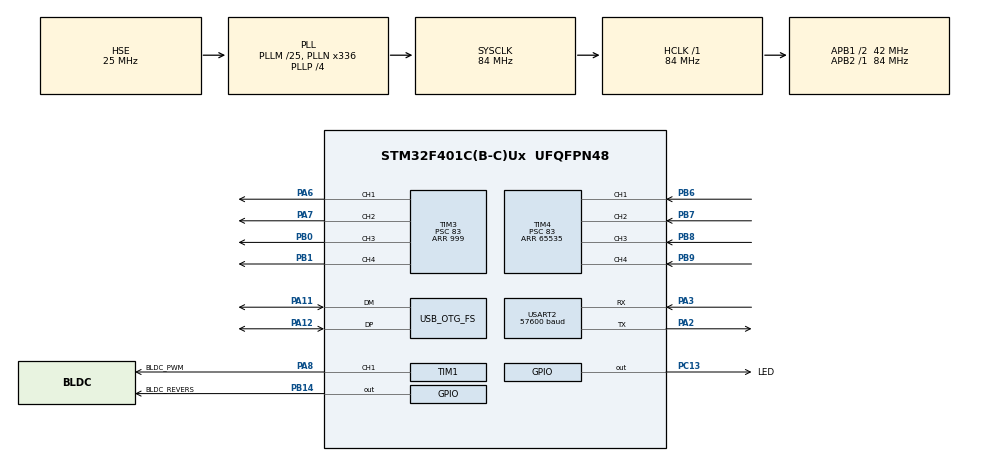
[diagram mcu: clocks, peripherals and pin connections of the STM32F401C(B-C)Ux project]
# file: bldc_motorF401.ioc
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Dma.Request0=USART2_RX
Dma.Request1=USART2_TX
Dma.USART2_RX.0.Direction=DMA_PERIPH_TO_MEMORY
Dma.USART2_RX.0.FIFOMode=DMA_FIFOMODE_DISABLE
Dma.USART2_RX.0.Instance=DMA1_Stream5
Dma.USART2_RX.0.MemDataAlignment=DMA_MDATAALIGN_BYTE
Dma.USART2_RX.0.MemInc=DMA_MINC_ENABLE
Dma.USART2_RX.0.Mode=DMA_NORMAL
Dma.USART2_RX.0.PeriphDataAlignment=DMA_PDATAALIGN_BYTE
Dma.USART2_RX.0.PeriphInc=DMA_PINC_DISABLE
Dma.USART2_RX.0.Priority=DMA_PRIORITY_LOW
Dma.USART2_TX.1.Direction=DMA_MEMORY_TO_PERIPH
Dma.USART2_TX.1.FIFOMode=DMA_FIFOMODE_DISABLE
Dma.USART2_TX.1.Instance=DMA1_Stream6
Dma.USART2_TX.1.MemDataAlignment=DMA_MDATAALIGN_BYTE
Dma.USART2_TX.1.MemInc=DMA_MINC_ENABLE
Dma.USART2_TX.1.Mode=DMA_NORMAL
Dma.USART2_TX.1.PeriphDataAlignment=DMA_PDATAALIGN_BYTE
Dma.USART2_TX.1.PeriphInc=DMA_PINC_DISABLE
Dma.USART2_TX.1.Priority=DMA_PRIORITY_LOW
Mcu.Family=STM32F4
Mcu.Name=STM32F401C(B-C)Ux
Mcu.Package=UFQFPN48
NVIC.DMA1_Stream5_IRQn=true\:0\:0\:false\:false\:true\:false\:true
NVIC.DMA1_Stream6_IRQn=true\:0\:0\:false\:false\:true\:false\:true
NVIC.OTG_FS_IRQn=true\:0\:0\:false\:false\:true\:false\:true
NVIC.PriorityGroup=NVIC_PRIORITYGROUP_4
NVIC.TIM4_IRQn=true\:0\:0\:false\:false\:true\:true\:true
NVIC.USART2_IRQn=true\:0\:0\:false\:false\:true\:true\:true
PA11.Mode=Device_Only
PA11.Signal=USB_OTG_FS_DM
PA12.Mode=Device_Only
PA12.Signal=USB_OTG_FS_DP
PA13.Mode=Serial_Wire
PA13.Signal=SYS_JTMS-SWDIO
PA14.Mode=Serial_Wire
PA14.Signal=SYS_JTCK-SWCLK
PA2.Mode=Asynchronous
PA2.Signal=USART2_TX
PA3.Mode=Asynchronous
PA3.Signal=USART2_RX
PA6.Signal=S_TIM3_CH1
PA7.Signal=S_TIM3_CH2
PA8.GPIO_Label=BLDC_PWM
PA8.GPIO_ModeDefaultPP=GPIO_MODE_AF_OD
PA8.GPIO_Speed=GPIO_SPEED_FREQ_VERY_HIGH
PA8.Signal=S_TIM1_CH1
PB0.Signal=S_TIM3_CH3
PB1.Signal=S_TIM3_CH4
PB14.GPIO_Label=BLDC_REVERS
PB14.GPIO_ModeDefaultOutputPP=GPIO_MODE_OUTPUT_OD
PB14.GPIO_PuPd=GPIO_NOPULL
PB14.Signal=GPIO_Output
PB6.Signal=S_TIM4_CH1
PB7.Signal=S_TIM4_CH2
PB8.Signal=S_TIM4_CH3
PB9.Signal=S_TIM4_CH4
PC13-ANTI_TAMP.GPIO_Label=LED
PC13-ANTI_TAMP.Signal=GPIO_Output
PC14-OSC32_IN.Mode=LSE-External-Oscillator
PC14-OSC32_IN.Signal=RCC_OSC32_IN
PC15-OSC32_OUT.Mode=LSE-External-Oscillator
PC15-OSC32_OUT.Signal=RCC_OSC32_OUT
PH0\ -\ OSC_IN.Mode=HSE-External-Oscillator
PH0\ -\ OSC_IN.Signal=RCC_OSC_IN
PH1\ -\ OSC_OUT.Mode=HSE-External-Oscillator
PH1\ -\ OSC_OUT.Signal=RCC_OSC_OUT
ProjectManager.HeapSize=0x600
ProjectManager.StackSize=0x400
ProjectManager.TargetToolchain=STM32CubeIDE
RCC.48MHZClocksFreq_Value=48000000
RCC.AHBFreq_Value=84000000
RCC.APB1CLKDivider=RCC_HCLK_DIV2
RCC.APB1Freq_Value=42000000
RCC.APB1TimFreq_Value=84000000
RCC.APB2Freq_Value=84000000
RCC.APB2TimFreq_Value=84000000
RCC.CortexFreq_Value=84000000
RCC.HCLKFreq_Value=84000000
RCC.HSE_VALUE=25000000
RCC.HSI_VALUE=16000000
RCC.PLLM=25
RCC.PLLN=336
RCC.PLLP=RCC_PLLP_DIV4
RCC.PLLQ=7
RCC.RCC_RTC_Clock_Source=RCC_RTCCLKSOURCE_LSE
RCC.RCC_RTC_Clock_SourceVirtual=RCC_RTCCLKSOURCE_LSE
RCC.SYSCLKFreq_VALUE=84000000
RCC.SYSCLKSource=RCC_SYSCLKSOURCE_PLLCLK
RCC.VCOOutputFreq_Value=336000000
RTC.Alarm=RTC_ALARM_A
SH.S_TIM1_CH1.0=TIM1_CH1,PWM Generation1 CH1
SH.S_TIM3_CH1.0=TIM3_CH1,PWM Generation1 CH1
SH.S_TIM3_CH2.0=TIM3_CH2,PWM Generation2 CH2
SH.S_TIM3_CH3.0=TIM3_CH3,PWM Generation3 CH3
SH.S_TIM3_CH4.0=TIM3_CH4,PWM Generation4 CH4
SH.S_TIM4_CH1.0=TIM4_CH1,Input_Capture1_from_TI1
SH.S_TIM4_CH2.0=TIM4_CH2,Input_Capture2_from_TI2
SH.S_TIM4_CH3.0=TIM4_CH3,Input_Capture3_from_TI3
SH.S_TIM4_CH4.0=TIM4_CH4,Input_Capture4_from_TI4
TIM1.Channel-PWM\ Generation1\ CH1=TIM_CHANNEL_1
TIM1.Period=999
TIM1.Prescaler=83
TIM3.Channel-PWM\ Generation1\ CH1=TIM_CHANNEL_1
TIM3.Channel-PWM\ Generation2\ CH2=TIM_CHANNEL_2
TIM3.Channel-PWM\ Generation3\ CH3=TIM_CHANNEL_3
TIM3.Channel-PWM\ Generation4\ CH4=TIM_CHANNEL_4
TIM3.Period=999
TIM3.Prescaler=83
TIM4.Channel-Input_Capture1_from_TI1=TIM_CHANNEL_1
TIM4.Channel-Input_Capture2_from_TI2=TIM_CHANNEL_2
TIM4.Channel-Input_Capture3_from_TI3=TIM_CHANNEL_3
TIM4.Channel-Input_Capture4_from_TI4=TIM_CHANNEL_4
TIM4.Period=65535
TIM4.Prescaler=83
USART2.BaudRate=57600
USART2.VirtualMode=VM_ASYNC
USB_DEVICE.CLASS_NAME_FS=CDC
USB_DEVICE.VirtualMode=Cdc
USB_DEVICE.VirtualModeFS=Cdc_FS
USB_OTG_FS.VirtualMode=Device_Only
VP_RTC_VS_RTC_Activate.Mode=RTC_Enabled
VP_RTC_VS_RTC_Alarm_A_Intern.Mode=Alarm A
VP_RTC_VS_RTC_Calendar.Mode=RTC_Calendar
VP_TIM1_VS_ClockSourceINT.Mode=Internal
VP_TIM3_VS_ClockSourceINT.Mode=Internal
VP_TIM4_VS_ClockSourceINT.Mode=Internal
VP_USB_DEVICE_VS_USB_DEVICE_CDC_FS.Mode=CDC_FS
board=custom

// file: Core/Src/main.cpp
/* USER CODE BEGIN Header */
/**
  ******************************************************************************
  * @file           : main.c
  * @brief          : Main program body
  ******************************************************************************
  * @attention
  *
  * Copyright (c) 2022 STMicroelectronics.
  * All rights reserved.
  *
  * This software is licensed under terms that can be found in the LICENSE file
  * in the root directory of this software component.
  * If no LICENSE file comes with this software, it is provided AS-IS.
  *
  ******************************************************************************
  */
/* USER CODE END Header */
#include "main.h"
#include "dma.h"
#include "rtc.h"
#include "tim.h"
#include "usart.h"
#include "usb_device.h"
#include "gpio.h"

/* USER CODE BEGIN Includes */
#include "../App/ros_main.h"
/* USER CODE END Includes */

void SystemClock_Config(void);

int main(void)
{

  /* MCU Configuration--------------------------------------------------------*/

  /* Reset of all peripherals, Initializes the Flash interface and the Systick. */
  HAL_Init();

  /* Configure the system clock */
  SystemClock_Config();

  /* Initialize all configured peripherals */
  MX_GPIO_Init();
  MX_USB_DEVICE_Init();
  MX_RTC_Init();
  MX_DMA_Init();
  MX_TIM1_Init();
  MX_USART2_UART_Init();
  MX_TIM3_Init();
  MX_TIM4_Init();
  /* USER CODE BEGIN 2 */
  setup();
  /* USER CODE END 2 */

  /* Infinite loop */
  /* USER CODE BEGIN WHILE */
  while (1)
  {
    loop();
    /* USER CODE END WHILE */

  }
}

void SystemClock_Config(void)
{
  RCC_OscInitTypeDef RCC_OscInitStruct = {0};
  RCC_ClkInitTypeDef RCC_ClkInitStruct = {0};

  /** Configure the main internal regulator output voltage
  */
  __HAL_RCC_PWR_CLK_ENABLE();
  __HAL_PWR_VOLTAGESCALING_CONFIG(PWR_REGULATOR_VOLTAGE_SCALE2);
  /** Initializes the RCC Oscillators according to the specified parameters
  * in the RCC_OscInitTypeDef structure.
  */
  RCC_OscInitStruct.OscillatorType = RCC_OSCILLATORTYPE_HSE|RCC_OSCILLATORTYPE_LSE;
  RCC_OscInitStruct.HSEState = RCC_HSE_ON;
  RCC_OscInitStruct.LSEState = RCC_LSE_ON;
  RCC_OscInitStruct.PLL.PLLState = RCC_PLL_ON;
  RCC_OscInitStruct.PLL.PLLSource = RCC_PLLSOURCE_HSE;
  RCC_OscInitStruct.PLL.PLLM = 25;
  RCC_OscInitStruct.PLL.PLLN = 336;
  RCC_OscInitStruct.PLL.PLLP = RCC_PLLP_DIV4;
  RCC_OscInitStruct.PLL.PLLQ = 7;
  if (HAL_RCC_OscConfig(&RCC_OscInitStruct) != HAL_OK)
  {
    Error_Handler();
  }
  /** Initializes the CPU, AHB and APB buses clocks
  */
  RCC_ClkInitStruct.ClockType = RCC_CLOCKTYPE_HCLK|RCC_CLOCKTYPE_SYSCLK
                              |RCC_CLOCKTYPE_PCLK1|RCC_CLOCKTYPE_PCLK2;
  RCC_ClkInitStruct.SYSCLKSource = RCC_SYSCLKSOURCE_PLLCLK;
  RCC_ClkInitStruct.AHBCLKDivider = RCC_SYSCLK_DIV1;
  RCC_ClkInitStruct.APB1CLKDivider = RCC_HCLK_DIV2;
  RCC_ClkInitStruct.APB2CLKDivider = RCC_HCLK_DIV1;

  if (HAL_RCC_ClockConfig(&RCC_ClkInitStruct, FLASH_LATENCY_2) != HAL_OK)
  {
    Error_Handler();
  }
}

void Error_Handler(void)
{
  __disable_irq();
  while (1)
  {
  }
}
